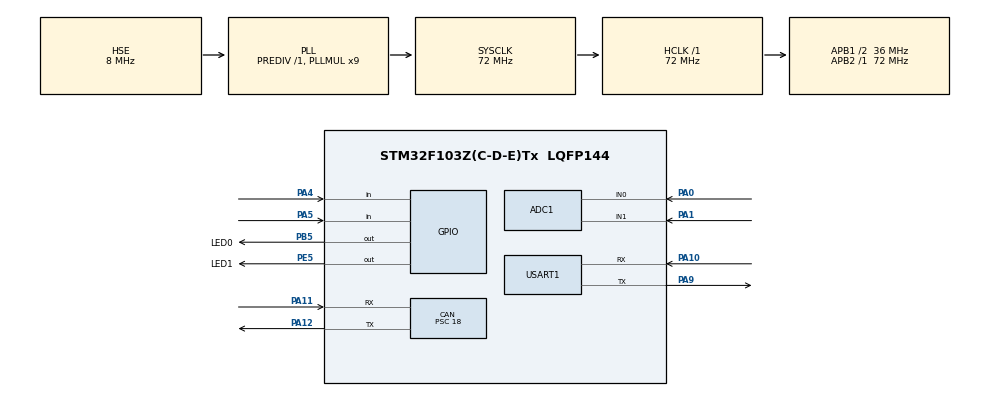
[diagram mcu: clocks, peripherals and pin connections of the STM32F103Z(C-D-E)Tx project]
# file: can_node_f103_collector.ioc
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ADC1.Channel-1\#ChannelRegularConversion=ADC_CHANNEL_0
ADC1.Channel-3\#ChannelRegularConversion=ADC_CHANNEL_1
ADC1.ContinuousConvMode=ENABLE
ADC1.EnableInjectedConversion=DISABLE
ADC1.NbrOfConversion=2
ADC1.NbrOfConversionFlag=1
ADC1.Rank-1\#ChannelRegularConversion=1
ADC1.Rank-3\#ChannelRegularConversion=2
ADC1.SamplingTime-1\#ChannelRegularConversion=ADC_SAMPLETIME_239CYCLES_5
ADC1.SamplingTime-3\#ChannelRegularConversion=ADC_SAMPLETIME_239CYCLES_5
ADC1.master=1
CAN.BS1=CAN_BS1_13TQ
CAN.BS2=CAN_BS2_2TQ
CAN.CalculateBaudRate=125000
CAN.CalculateTimeBit=8000
CAN.CalculateTimeQuantum=500.0
CAN.Mode=CAN_MODE_NORMAL
CAN.NART=ENABLE
CAN.Prescaler=18
Dma.ADC1.0.Direction=DMA_PERIPH_TO_MEMORY
Dma.ADC1.0.Instance=DMA1_Channel1
Dma.ADC1.0.MemDataAlignment=DMA_MDATAALIGN_HALFWORD
Dma.ADC1.0.MemInc=DMA_MINC_ENABLE
Dma.ADC1.0.Mode=DMA_CIRCULAR
Dma.ADC1.0.PeriphDataAlignment=DMA_PDATAALIGN_HALFWORD
Dma.ADC1.0.PeriphInc=DMA_PINC_DISABLE
Dma.ADC1.0.Priority=DMA_PRIORITY_LOW
Dma.Request0=ADC1
FREERTOS.Tasks01=defaultTask,24,128,StartDefaultTask,Default,NULL,Dynamic,NULL,NULL
FREERTOS.configCHECK_FOR_STACK_OVERFLOW=2
FREERTOS.configTOTAL_HEAP_SIZE=4096
FREERTOS.configUSE_MALLOC_FAILED_HOOK=1
IWDG.Prescaler=IWDG_PRESCALER_64
IWDG.Reload=1250
Mcu.Family=STM32F1
Mcu.Name=STM32F103Z(C-D-E)Tx
Mcu.Package=LQFP144
NVIC.DMA1_Channel1_IRQn=true\:5\:0\:false\:false\:true\:true\:false\:true\:true
NVIC.PriorityGroup=NVIC_PRIORITYGROUP_4
NVIC.RTC_Alarm_IRQn=true\:5\:0\:false\:false\:true\:true\:true\:true\:true
NVIC.USART1_IRQn=true\:5\:0\:true\:false\:true\:true\:true\:true\:true
NVIC.USB_LP_CAN1_RX0_IRQn=true\:5\:0\:false\:false\:true\:true\:true\:true\:true
OSC_IN.Mode=HSE-External-Oscillator
OSC_IN.Signal=RCC_OSC_IN
OSC_OUT.Mode=HSE-External-Oscillator
OSC_OUT.Signal=RCC_OSC_OUT
PA0-WKUP.Signal=ADCx_IN0
PA1.Signal=ADCx_IN1
PA10.Mode=Asynchronous
PA10.Signal=USART1_RX
PA11.Mode=CAN_Activate
PA11.Signal=CAN_RX
PA12.Mode=CAN_Activate
PA12.Signal=CAN_TX
PA13.Mode=Serial_Wire
PA13.Signal=SYS_JTMS-SWDIO
PA14.Mode=Serial_Wire
PA14.Signal=SYS_JTCK-SWCLK
PA4.GPIO_PuPd=GPIO_PULLUP
PA4.Signal=GPIO_Input
PA5.GPIO_PuPd=GPIO_PULLUP
PA5.Signal=GPIO_Input
PA9.Mode=Asynchronous
PA9.Signal=USART1_TX
PB5.GPIO_Label=LED0
PB5.GPIO_ModeDefaultOutputPP=GPIO_MODE_OUTPUT_PP
PB5.GPIO_PuPd=GPIO_NOPULL
PB5.PinState=GPIO_PIN_RESET
PB5.Signal=GPIO_Output
PC14-OSC32_IN.Mode=LSE-External-Oscillator
PC14-OSC32_IN.Signal=RCC_OSC32_IN
PC15-OSC32_OUT.Mode=LSE-External-Oscillator
PC15-OSC32_OUT.Signal=RCC_OSC32_OUT
PE5.GPIO_Label=LED1
PE5.GPIO_ModeDefaultOutputPP=GPIO_MODE_OUTPUT_PP
PE5.GPIO_PuPd=GPIO_NOPULL
PE5.PinState=GPIO_PIN_RESET
PE5.Signal=GPIO_Output
ProjectManager.HeapSize=0x200
ProjectManager.StackSize=0x400
ProjectManager.TargetToolchain=MDK-ARM V5.32
RCC.ADCPresc=RCC_ADCPCLK2_DIV6
RCC.AHBFreq_Value=72000000
RCC.APB1CLKDivider=RCC_HCLK_DIV2
RCC.APB1Freq_Value=36000000
RCC.APB1TimFreq_Value=72000000
RCC.APB2Freq_Value=72000000
RCC.APB2TimFreq_Value=72000000
RCC.HCLKFreq_Value=72000000
RCC.PLLMUL=RCC_PLL_MUL9
RCC.PLLSourceVirtual=RCC_PLLSOURCE_HSE
RCC.RTCClockSelection=RCC_RTCCLKSOURCE_LSE
RCC.SYSCLKFreq_VALUE=72000000
RCC.SYSCLKSource=RCC_SYSCLKSOURCE_PLLCLK
RCC.USBFreq_Value=72000000
RTC.Hours=12
SH.ADCx_IN0.0=ADC1_IN0,IN0
SH.ADCx_IN1.0=ADC1_IN1,IN1
USART1.VirtualMode=VM_ASYNC
VP_FREERTOS_VS_CMSIS_V2.Mode=CMSIS_V2
VP_IWDG_VS_IWDG.Mode=IWDG_Activate
VP_RTC_VS_RTC_Activate.Mode=RTC_Enabled
VP_RTC_VS_RTC_Calendar.Mode=RTC_Calendar
board=custom

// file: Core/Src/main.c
/* USER CODE BEGIN Header */
/**
  ******************************************************************************
  * @file           : main.c
  * @brief          : Main program body
  ******************************************************************************
  * @attention
  *
  * Copyright (c) 2026 STMicroelectronics.
  * All rights reserved.
  *
  * This software is licensed under terms that can be found in the LICENSE file
  * in the root directory of this software component.
  * If no LICENSE file comes with this software, it is provided AS-IS.
  *
  ******************************************************************************
  */
/* USER CODE END Header */
#include "main.h"
#include "cmsis_os.h"
#include "adc.h"
#include "can.h"
#include "dma.h"
#include "iwdg.h"
#include "rtc.h"
#include "usart.h"
#include "gpio.h"

/* USER CODE BEGIN Includes */
#include <stdio.h>
#include "bsp_adc.h"
#include "bsp_can.h"
#include "bsp_gpio.h"
#include "app_main.h"

/* USER CODE END Includes */

void SystemClock_Config(void);
void MX_FREERTOS_Init(void);

/* USER CODE BEGIN 0 */
//printf重定向
int fputc(int ch, FILE *f)
{
    HAL_UART_Transmit(&huart1, (uint8_t *)&ch, 1, 0xffff);
    return ch;
}

/* USER CODE END 0 */

int main(void)
{

  /* MCU Configuration--------------------------------------------------------*/

  /* Reset of all peripherals, Initializes the Flash interface and the Systick. */
  HAL_Init();

  /* Configure the system clock */
  SystemClock_Config();

  /* Initialize all configured peripherals */
  MX_GPIO_Init();
  MX_DMA_Init();
  MX_USART1_UART_Init();
  MX_ADC1_Init();
  MX_CAN_Init();
  MX_IWDG_Init();
  MX_RTC_Init();

  /* Init scheduler */
  osKernelInitialize();  /* Call init function for freertos objects (in cmsis_os2.c) */
  MX_FREERTOS_Init();

  /* Start scheduler */
  osKernelStart();

  /* We should never get here as control is now taken by the scheduler */

  /* Infinite loop */
  while (1)
  {

  }
}

void SystemClock_Config(void)
{
  RCC_OscInitTypeDef RCC_OscInitStruct = {0};
  RCC_ClkInitTypeDef RCC_ClkInitStruct = {0};
  RCC_PeriphCLKInitTypeDef PeriphClkInit = {0};

  /** Initializes the RCC Oscillators according to the specified parameters
  * in the RCC_OscInitTypeDef structure.
  */
  RCC_OscInitStruct.OscillatorType = RCC_OSCILLATORTYPE_LSI|RCC_OSCILLATORTYPE_HSE
                              |RCC_OSCILLATORTYPE_LSE;
  RCC_OscInitStruct.HSEState = RCC_HSE_ON;
  RCC_OscInitStruct.HSEPredivValue = RCC_HSE_PREDIV_DIV1;
  RCC_OscInitStruct.LSEState = RCC_LSE_ON;
  RCC_OscInitStruct.HSIState = RCC_HSI_ON;
  RCC_OscInitStruct.LSIState = RCC_LSI_ON;
  RCC_OscInitStruct.PLL.PLLState = RCC_PLL_ON;
  RCC_OscInitStruct.PLL.PLLSource = RCC_PLLSOURCE_HSE;
  RCC_OscInitStruct.PLL.PLLMUL = RCC_PLL_MUL9;
  if (HAL_RCC_OscConfig(&RCC_OscInitStruct) != HAL_OK)
  {
    Error_Handler();
  }

  /** Initializes the CPU, AHB and APB buses clocks
  */
  RCC_ClkInitStruct.ClockType = RCC_CLOCKTYPE_HCLK|RCC_CLOCKTYPE_SYSCLK
                              |RCC_CLOCKTYPE_PCLK1|RCC_CLOCKTYPE_PCLK2;
  RCC_ClkInitStruct.SYSCLKSource = RCC_SYSCLKSOURCE_PLLCLK;
  RCC_ClkInitStruct.AHBCLKDivider = RCC_SYSCLK_DIV1;
  RCC_ClkInitStruct.APB1CLKDivider = RCC_HCLK_DIV2;
  RCC_ClkInitStruct.APB2CLKDivider = RCC_HCLK_DIV1;

  if (HAL_RCC_ClockConfig(&RCC_ClkInitStruct, FLASH_LATENCY_2) != HAL_OK)
  {
    Error_Handler();
  }
  PeriphClkInit.PeriphClockSelection = RCC_PERIPHCLK_RTC|RCC_PERIPHCLK_ADC;
  PeriphClkInit.RTCClockSelection = RCC_RTCCLKSOURCE_LSE;
  PeriphClkInit.AdcClockSelection = RCC_ADCPCLK2_DIV6;
  if (HAL_RCCEx_PeriphCLKConfig(&PeriphClkInit) != HAL_OK)
  {
    Error_Handler();
  }
}

void Error_Handler(void)
{
  __disable_irq();
  while (1)
  {
  }
}

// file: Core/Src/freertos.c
/* USER CODE BEGIN Header */
/**
  ******************************************************************************
  * File Name          : freertos.c
  * Description        : Code for freertos applications
  ******************************************************************************
  * @attention
  *
  * Copyright (c) 2026 STMicroelectronics.
  * All rights reserved.
  *
  * This software is licensed under terms that can be found in the LICENSE file
  * in the root directory of this software component.
  * If no LICENSE file comes with this software, it is provided AS-IS.
  *
  ******************************************************************************
  */
/* USER CODE END Header */

#include "FreeRTOS.h"
#include "task.h"
#include "main.h"
#include "cmsis_os.h"

/* USER CODE BEGIN Includes */
#include "app_main.h"
/* USER CODE END Includes */

/* Definitions for defaultTask */
osThreadId_t defaultTaskHandle;
const osThreadAttr_t defaultTask_attributes = {
  .name = "defaultTask",
  .stack_size = 128 * 4,
  .priority = (osPriority_t) osPriorityNormal,
};

void StartDefaultTask(void *argument);

void MX_FREERTOS_Init(void); /* (MISRA C 2004 rule 8.1) */

/* Hook prototypes */
void vApplicationStackOverflowHook(xTaskHandle xTask, signed char *pcTaskName);
void vApplicationMallocFailedHook(void);

/* USER CODE BEGIN 4 */
//void vApplicationStackOverflowHook(xTaskHandle xTask, signed char *pcTaskName)
//{
   /* Run time stack overflow checking is performed if
   configCHECK_FOR_STACK_OVERFLOW is defined to 1 or 2. This hook function is
   called if a stack overflow is detected. */
//}

/* USER CODE END 4 */

/* USER CODE BEGIN 5 */
//void vApplicationMallocFailedHook(void)
//{
   /* vApplicationMallocFailedHook() will only be called if
   configUSE_MALLOC_FAILED_HOOK is set to 1 in FreeRTOSConfig.h. It is a hook
   function that will get called if a call to pvPortMalloc() fails.
   pvPortMalloc() is called internally by the kernel whenever a task, queue,
   timer or semaphore is created. It is also called by various parts of the
   demo application. If heap_1.c or heap_2.c are used, then the size of the
   heap available to pvPortMalloc() is defined by configTOTAL_HEAP_SIZE in
   FreeRTOSConfig.h, and the xPortGetFreeHeapSize() API function can be used
   to query the size of free heap space that remains (although it does not
   provide information on how the remaining heap might be fragmented). */
//}
/* USER CODE END 5 */

void MX_FREERTOS_Init(void) {

  /* Create the thread(s) */
  /* creation of defaultTask */
  defaultTaskHandle = osThreadNew(StartDefaultTask, NULL, &defaultTask_attributes);

}

void StartDefaultTask(void *argument)
{
  /* USER CODE BEGIN StartDefaultTask */
	App_SystemInit();    //调用业务初始化，创建队列、业务任务
  vTaskDelete(NULL);   //执行完直接自杀，不再进入死循环
  /* Infinite loop */
  for(;;)
  {
    osDelay(1);
  }
  /* USER CODE END StartDefaultTask */
}
